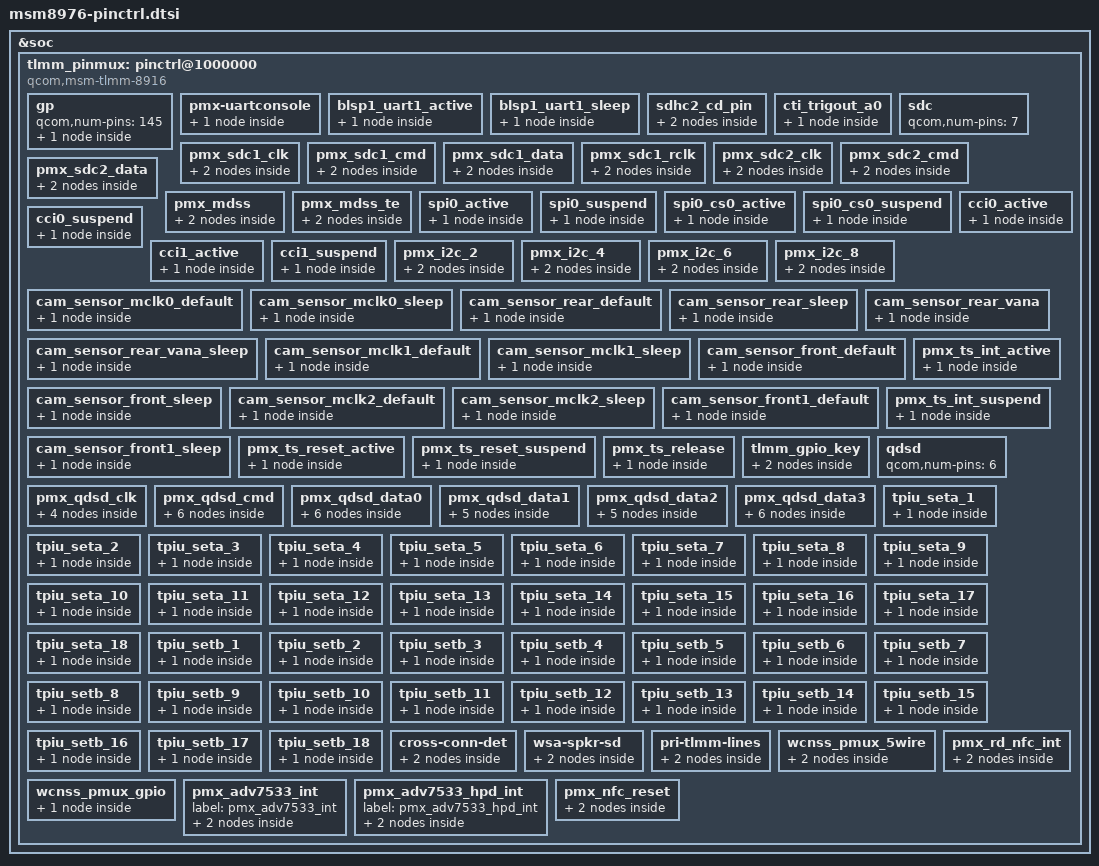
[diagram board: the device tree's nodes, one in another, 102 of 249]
/*
 * Copyright (c) 2014-2015, The Linux Foundation. All rights reserved.
 *
 * This program is free software; you can redistribute it and/or modify
 * it under the terms of the GNU General Public License version 2 and
 * only version 2 as published by the Free Software Foundation.
 *
 * This program is distributed in the hope that it will be useful,
 * but WITHOUT ANY WARRANTY; without even the implied warranty of
 * MERCHANTABILITY or FITNESS FOR A PARTICULAR PURPOSE.  See the
 * GNU General Public License for more details.
 */

&soc {
	tlmm_pinmux: pinctrl@1000000 {
		compatible = "qcom,msm-tlmm-8916";
		reg = <0x1000000 0x300000>;
		interrupts = <0 208 0>;

		/*General purpose pins*/
		gp: gp {
			qcom,num-pins = <145>;
			#qcom,pin-cells = <1>;
			msm_gpio: msm_gpio {
				compatible = "qcom,msm-tlmm-gp";
				gpio-controller;
				#gpio-cells = <2>;
				interrupt-controller;
				#interrupt-cells = <2>;
				num_irqs = <145>;
			};
		};

		pmx-uartconsole {
			qcom,pins = <&gp 4>, <&gp 5>;
			qcom,num-grp-pins = <2>;
			qcom,pin-func = <2>;
			label = "uart-console";
			uart_console_sleep: uart-console {
				drive-strength = <2>;
				bias-pull-down;
			};
		};

		blsp1_uart1_active {
			qcom,pins = <&gp 0>, <&gp 1>, <&gp 2>, <&gp 3>;
			qcom,num-grp-pins = <4>;
			qcom,pin-func = <2>;
			label = "blsp1_uart1_active";
			hsuart_active: default {
				drive-strength = <16>;
				bias-disable;
			};
		 };

		blsp1_uart1_sleep {
			qcom,pins = <&gp 0>, <&gp 1>, <&gp 2>, <&gp 3>;
			qcom,num-grp-pins = <4>;
			qcom,pin-func = <0>;
			label = "blsp1_uart1_sleep";
			hsuart_sleep: sleep {
				drive-strength = <2>;
				bias-disable;
			};
		};

		sdhc2_cd_pin {
			qcom,pins = <&gp 100>;
			qcom,num-grp-pins = <1>;
			qcom,pin-func = <0>;
			label = "cd-gpio";
			sdc2_cd_on: cd_on {
				drive-strength = <2>;
				bias-pull-up;
			};
			sdc2_cd_off: cd_off {
				drive-strength = <2>;
				bias-disable;
			};
		};

		cti_trigout_a0 {
			qcom,pins = <&gp 32>;
			qcom,num-grp-pins = <1>;
			qcom,pin-func = <8>;
			label = "cti-trigout-a0";
			trigout_a0: trigout_a0 {
				drive-strength = <2>;
				bias-disable;
			};
		};

		/* SDC pin type */
		sdc: sdc {
			/*
			 * 0-3 for sdc1
			 * 4-6 for sdc2
			 */
			qcom,num-pins = <7>;
			/*
			 * Order of pins:
			 * SDC1: CLK -> 0, CMD -> 1, DATA -> 2, RCLK -> 3
			 * SDC2: CLK -> 4, CMD -> 5, DATA -> 6
			 */
			#qcom,pin-cells = <1>;
		};

		pmx_sdc1_clk {
			qcom,pins = <&sdc 0>;
			qcom,num-grp-pins = <1>;
			label = "sdc1-clk";
			sdc1_clk_on: clk_on {
				bias-disable; /* NO pull */
				drive-strength = <16>; /* 16 MA */
			};
			sdc1_clk_off: clk_off {
				bias-disable; /* NO pull */
				drive-strength = <2>; /* 2 MA */
			};
		};

		pmx_sdc1_cmd {
			qcom,pins = <&sdc 1>;
			qcom,num-grp-pins = <1>;
			label = "sdc1-cmd";
			sdc1_cmd_on: cmd_on {
				bias-pull-up; /* pull up */
				drive-strength = <10>; /* 10 MA */
			};
			sdc1_cmd_off: cmd_off {
				bias-pull-up; /* pull up */
				drive-strength = <2>; /* 2 MA */
			};
		};

		pmx_sdc1_data {
			qcom,pins = <&sdc 2>;
			qcom,num-grp-pins = <1>;
			label = "sdc1-data";
			sdc1_data_on: data_on {
				bias-pull-up; /* pull up */
				drive-strength = <10>; /* 10 MA */
			};
			sdc1_data_off: data_off {
				bias-pull-up; /* pull up */
				drive-strength = <2>; /* 2 MA */
			};
		};

		pmx_sdc1_rclk {
			qcom,pins = <&sdc 3>;
			qcom,num-grp-pins = <1>;
			label = "sdc1-rclk";
			sdc1_rclk_on: rclk_on {
				bias-pull-down; /* pull down */
			};

			sdc1_rclk_off: rclk_off {
				bias-pull-down; /* pull down */
			};
		};

		pmx_sdc2_clk {
			qcom,pins = <&sdc 4>;
			qcom,num-grp-pins = <1>;
			label = "sdc2-clk";
			sdc2_clk_on: clk_on {
				bias-disable; /* NO pull */
				drive-strength = <16>; /* 16 MA */
			};
			sdc2_clk_off: clk_off {
				bias-disable; /* NO pull */
				drive-strength = <2>; /* 2 MA */
			};
		};

		pmx_sdc2_cmd {
			qcom,pins = <&sdc 5>;
			qcom,num-grp-pins = <1>;
			label = "sdc2-cmd";
			sdc2_cmd_on: cmd_on {
				bias-pull-up; /* pull up */
				drive-strength = <10>; /* 10 MA */
			};
			sdc2_cmd_off: cmd_off {
				bias-pull-up; /* pull up */
				drive-strength = <2>; /* 2 MA */
			};
		};

		pmx_sdc2_data {
			qcom,pins = <&sdc 6>;
			qcom,num-grp-pins = <1>;
			label = "sdc2-data";
			sdc2_data_on: data_on {
				bias-pull-up; /* pull up */
				drive-strength = <10>; /* 10 MA */
			};
			sdc2_data_off: data_off {
				bias-pull-up; /* pull up */
				drive-strength = <2>; /* 2 MA */
			};
		};

		pmx_mdss: pmx_mdss {
			label = "mdss-pins";
			qcom,pin-func = <0>;
			mdss_dsi_active: active {
				drive-strength = <8>; /* 8 mA */
				bias-disable = <0>; /* no pull */
				output-high;
			};

			mdss_dsi_suspend: suspend {
				drive-strength = <2>; /* 2 mA */
				bias-pull-down; /* pull down */
				output-low;
			};
		};

		pmx_mdss_te: pmx_mdss_te {
			label = "mdss-te-pin";
			qcom,pin-func = <1>;
			mdss_te_active: active {
				drive-strength = <2>; /* 2 mA */
				bias-pull-down; /* pull down */
				input-debounce = <0>;
			};

			mdss_te_suspend: suspend {
				drive-strength = <2>; /* 2 mA */
				bias-pull-down; /* pull down */
				input-debounce = <0>;
			};
		};

		spi0_active {
			/* MOSI, MISO, CLK */
			qcom,pins = <&gp 0>, <&gp 1>, <&gp 3>;
			qcom,num-grp-pins = <3>;
			qcom,pin-func = <1>;
			label = "spi0-active";
			/* active state */
			spi0_default: spi0_default {
				drive-strength = <12>; /* 12 MA */
				bias-disable = <0>; /* No PULL */
			};
		};

		spi0_suspend {
			/* MOSI, MISO, CLK */
			qcom,pins = <&gp 0>, <&gp 1>, <&gp 3>;
			qcom,num-grp-pins = <3>;
			qcom,pin-func = <0>;
			label = "spi0-suspend";
			/* suspended state */
			spi0_sleep: spi0_sleep {
				drive-strength = <2>; /* 2 MA */
				bias-pull-down; /* PULL Down */
			};
		};

		spi0_cs0_active {
			/* CS */
			qcom,pins = <&gp 2>;
			qcom,num-grp-pins = <1>;
			qcom,pin-func = <1>;
			label = "spi0-cs0-active";
			spi0_cs0_active: cs0_active {
				drive-strength = <2>;
				bias-disable = <0>;
			};
		};

		spi0_cs0_suspend {
			/* CS */
			qcom,pins = <&gp 2>;
			qcom,num-grp-pins = <1>;
			qcom,pin-func = <0>;
			label = "spi0-cs0-suspend";
			spi0_cs0_sleep: cs0_sleep {
				drive-strength = <2>;
				bias-disable = <0>;
			};
		};

		/* cci */
		cci0_active {
			/* CLK, DATA */
			qcom,pins = <&gp 30>, <&gp 29>;
			qcom,num-grp-pins = <2>;
			qcom,pin-func = <1>;
			label = "cci0-active";
			/* active state */
			cci0_active: cci0_active {
				drive-strength = <2>; /* 2 MA */
				bias-disable; /* No PULL */
			};
		};

		cci0_suspend {
			/* CLK, DATA */
			qcom,pins = <&gp 30>, <&gp 29>;
			qcom,num-grp-pins = <2>;
			qcom,pin-func = <0>;
			label = "cci0-suspend";
			/*suspended state */
			cci0_suspend: cci0_suspend {
				drive-strength = <2>; /* 2 MA */
				bias-disable; /* No PULL */
			};
		};

		cci1_active {
			/* CLK, DATA */
			qcom,pins = <&gp 104>, <&gp 103>;
			qcom,num-grp-pins = <2>;
			qcom,pin-func = <1>;
			label = "cci1-active";
			/* active state */
			cci1_active: cci1_active {
				drive-strength = <2>; /* 2 MA */
				bias-disable; /* No PULL */
			};
		};

		cci1_suspend {
			/* CLK, DATA */
			qcom,pins = <&gp 104>, <&gp 103>;
			qcom,num-grp-pins = <2>;
			qcom,pin-func = <0>;
			label = "cci1-suspend";
			/*suspended state */
			cci1_suspend: cci1_suspend {
				drive-strength = <2>; /* 2 MA */
				bias-disable; /* No PULL */
			};
		};

		pmx_i2c_2 {
                        /* CLK, DATA */
                        qcom,pins = <&gp 6>, <&gp 7>;
                        qcom,num-grp-pins = <2>;
                        qcom,pin-func = <3>;
                        label = "pmx_i2c_2";
			/* active state */
                        i2c_2_active: i2c_2_active {
				drive-strength = <2>; /* 2 MA */
				bias-disable = <0>; /* No PULL */
                        };
			/* suspend state */
                        i2c_2_sleep: i2c_2_sleep {
				drive-strength = <2>; /* 2 MA */
				bias-disable = <0>; /* No PULL */
                        };
                };

		pmx_i2c_4 {
			/* CLK, DATA */
			qcom,pins = <&gp 14>, <&gp 15>;
			qcom,num-grp-pins = <2>;
			qcom,pin-func = <3>;
			label = "pmx_i2c_4";
			/* active state */
			i2c_4_active: i2c_4_active {
				drive-strength = <2>; /* 2 MA */
				bias-disable = <0>; /* No PULL */
			};
                        /* suspended state */
                        i2c_4_sleep: i2c_4_sleep {
                                drive-strength = <2>; /* 2 MA */
                                bias-disable = <0>; /* No PULL */
                        };
                };

		pmx_i2c_6 {
			/* CLK, DATA */
			qcom,pins = <&gp 22>, <&gp 23>;
			qcom,num-grp-pins = <2>;
			qcom,pin-func = <3>;
			label = "pmx_i2c_6";
			/* active state */
			i2c_6_active: i2c_6_active{
				drive-strength = <2>; /* 2 MA */
				bias-disable; /* No PULL */
			};
			/* suspended state */
			i2c_6_sleep: i2c_6_sleep {
				drive-strength = <2>; /* 2 MA */
				bias-disable; /* No PULL */
			};
		};

		pmx_i2c_8 {
                        /* CLK, DATA */
                        qcom,pins = <&gp 18>, <&gp 19>;
                        qcom,num-grp-pins = <2>;
                        qcom,pin-func = <3>;
                        label = "pmx_i2c_8";
                        /* active state */
                        i2c_8_active: i2c_8_active{
                                drive-strength = <2>; /* 2 MA */
                                bias-disable; /* No PULL */
                        };
                        /* suspended state */
                        i2c_8_sleep: i2c_8_sleep {
                                drive-strength = <2>; /* 2 MA */
                                bias-disable; /* No PULL */
                        };
                };

		/*sensors */
		cam_sensor_mclk0_default {
			/* MCLK0 */
			qcom,pins = <&gp 26>;
			qcom,num-grp-pins = <1>;
			qcom,pin-func = <1>;
			label = "cam_sensor_mclk0_default";
			/* active state */
			cam_sensor_mclk0_default: cam_sensor_mclk0_default {
				drive-strength = <2>; /* 2 MA */
				bias-disable; /* No PULL */
			};
		};

		cam_sensor_mclk0_sleep {
			/* MCLK0 */
			qcom,pins = <&gp 26>;
			qcom,num-grp-pins = <1>;
			label = "cam_sensor_mclk0_sleep";
			/*suspended state */
			cam_sensor_mclk0_sleep: cam_sensor_mclk0_sleep {
				drive-strength = <2>; /* 2 MA */
				bias-pull-down; /* PULL DOWN */
			};
		};

		cam_sensor_rear_default {
			/* RESET, STANDBY */
			qcom,pins = <&gp 129>, <&gp 35>;
			qcom,num-grp-pins = <2>;
			label = "cam_sensor_rear_default";
			/* active state */
			cam_sensor_rear_default: cam_sensor_rear_default {
				drive-strength = <2>; /* 2 MA */
				bias-disable; /* No PULL */
			};
		};

		cam_sensor_rear_sleep {
			/* RESET, STANDBY */
			qcom,pins = <&gp 129>, <&gp 35>;
			qcom,num-grp-pins = <2>;
			label = "cam_sensor_rear_sleep";
			/*suspended state */
			cam_sensor_rear_sleep: cam_sensor_rear_sleep {
				drive-strength = <2>; /* 2 MA */
				bias-disable; /* No PULL */
			};
		};

		cam_sensor_rear_vana {
			/* VANA */
			qcom,pins = <&gp 63>;
			qcom,num-grp-pins = <1>;
			label = "cam_sensor_rear_vana";
			/* active state */
			cam_sensor_rear_vana: cam_sensor_rear_vana {
				drive-strength = <2>; /* 2 MA */
				bias-disable; /* No PULL */
			};
		};

		cam_sensor_rear_vana_sleep {
			/* VANA */
			qcom,pins = <&gp 63>;
			qcom,num-grp-pins = <1>;
			label = "cam_sensor_rear_vana_sleep";
			/*suspended state */
			cam_sensor_rear_vana_sleep: cam_sensor_rear_vana_sleep {
				drive-strength = <2>; /* 2 MA */
				bias-disable; /* No PULL */
			};
		};

		cam_sensor_mclk1_default {
			/* MCLK1 */
			qcom,pins = <&gp 27>;
			qcom,num-grp-pins = <1>;
			qcom,pin-func = <1>;
			label = "cam_sensor_mclk1_default";
			/* active state */
			cam_sensor_mclk1_default: cam_sensor_mclk1_default {
				drive-strength = <2>; /* 2 MA */
				bias-disable; /* No PULL */
			};
		};

		cam_sensor_mclk1_sleep {
			/* MCLK1 */
			qcom,pins = <&gp 27>;
			qcom,num-grp-pins = <1>;
			label = "cam_sensor_mclk1_sleep";
			/*suspended state */
			cam_sensor_mclk1_sleep: cam_sensor_mclk1_sleep {
				drive-strength = <2>; /* 2 MA */
				bias-pull-down; /* PULL DOWN */
			};
		};

		cam_sensor_front_default {
			/* RESET, STANDBY */
			qcom,pins = <&gp 130>, <&gp 36>;
			qcom,num-grp-pins = <2>;
			label = "cam_sensor_front_default";
			/* active state */
			cam_sensor_front_default: cam_sensor_front_default {
				drive-strength = <2>; /* 2 MA */
				bias-disable; /* No PULL */
			};
		};

		cam_sensor_front_sleep {
			/* RESET, STANDBY */
			qcom,pins = <&gp 130>, <&gp 36>;
			qcom,num-grp-pins = <2>;
			label = "cam_sensor_front_sleep";
			/*suspended state */
			cam_sensor_front_sleep: cam_sensor_front_sleep {
				drive-strength = <2>; /* 2 MA */
				bias-disable; /* No PULL */
			};
		};

		cam_sensor_mclk2_default {
			/* MCLK2 */
			qcom,pins = <&gp 28>;
			qcom,num-grp-pins = <1>;
			qcom,pin-func = <1>;
			label = "cam_sensor_mclk2_default";
			/* active state */
			cam_sensor_mclk2_default: cam_sensor_mclk2_default {
				drive-strength = <2>; /* 2 MA */
				bias-disable; /* No PULL */
			};
		};

		cam_sensor_mclk2_sleep {
			/* MCLK2 */
			qcom,pins = <&gp 28>;
			qcom,num-grp-pins = <1>;
			label = "cam_sensor_mclk2_sleep";
			/*suspended state */
			cam_sensor_mclk2_sleep: cam_sensor_mclk2_sleep {
				drive-strength = <2>; /* 2 MA */
				bias-pull-down; /* PULL DOWN */
			};
		};

		cam_sensor_front1_default {
			/* RESET, STANDBY */
			qcom,pins = <&gp 131>, <&gp 38>;
			qcom,num-grp-pins = <2>;
			label = "cam_sensor_front1_default";
			/* active state */
			cam_sensor_front1_default: cam_sensor_front1_default {
				drive-strength = <2>; /* 2 MA */
				bias-disable; /* No PULL */
			};
		};

		cam_sensor_front1_sleep {
			/* RESET, STANDBY */
			qcom,pins = <&gp 131>, <&gp 38>;
			qcom,num-grp-pins = <2>;
			label = "cam_sensor_front1_sleep";
			/*suspended state */
			cam_sensor_front1_sleep: cam_sensor_front1_sleep {
				drive-strength = <2>; /* 2 MA */
				bias-disable; /* No PULL */
			};
		};

		/* add pingrp for touchscreen */
		pmx_ts_int_active {
			qcom,pins = <&gp 65>;
			qcom,pin-func = <0>;
			qcom,num-grp-pins = <1>;
			label = "pmx_ts_int_active";

			ts_int_active: ts_int_active {
				drive-strength = <8>;
				bias-pull-up;
			};
		};

		pmx_ts_int_suspend {
			qcom,pins = <&gp 65>;
			qcom,pin-func = <0>;
			qcom,num-grp-pins = <1>;
			label = "pmx_ts_int_suspend";

			ts_int_suspend: ts_int_suspend {
				drive-strength = <2>;
				bias-pull-down;
			};
		};

		pmx_ts_reset_active {
			qcom,pins = <&gp 64>;
			qcom,pin-func = <0>;
			qcom,num-grp-pins = <1>;
			label = "pmx_ts_reset_active";

			ts_reset_active: ts_reset_active {
				drive-strength = <8>;
				bias-pull-up;
			};
		};

		pmx_ts_reset_suspend {
			qcom,pins = <&gp 64>;
			qcom,pin-func = <0>;
			qcom,num-grp-pins = <1>;
			label = "pmx_ts_reset_suspend";

			ts_reset_suspend: ts_reset_suspend {
				drive-strength = <2>;
				bias-pull-down;
			};
		};

		pmx_ts_release {
			qcom,pins = <&gp 65>, <&gp 64>;
			qcom,num-grp-pins = <2>;
			label = "pmx_ts_release";

			ts_release: ts_release {
				drive-strength = <2>;
				bias-pull-down;
			};
		};

		tlmm_gpio_key {
			qcom,pins = <&gp 113>, <&gp 114>, <&gp 115>;
			qcom,pin-func = <0>;
			qcom,num-grp-pins = <3>;
			label = "tlmm_gpio_key";

			gpio_key_active: gpio_key_active {
				drive-strength = <2>;
				bias-pull-up;
			};

			gpio_key_suspend: gpio_key_suspend {
				drive-strength = <2>;
				bias-pull-up;
			};
		};

		/* QDSD pin type */
		qdsd: qdsd {
			/* 0-> clk, 1 -> cmd, 2->data0, 3->data1, 4->data2, 5->data3 */
			qcom,num-pins = <6>;

			#qcom,pin-cells = <1>;
		};

		pmx_qdsd_clk {
			qcom,pins = <&qdsd 0>;
			qcom,num-grp-pins = <1>;
			label = "qdsd-clk";
			qdsd_clk_sdcard: clk_sdcard {
				bias-disable; /* NO pull */
				drive-strength = <7>; /* 7 MA */
			};

			qdsd_clk_trace: clk_trace {
				bias-pull-down; /* pull down */
				drive-strength = <0>; /* 0 MA */
			};

			qdsd_clk_swdtrc: clk_swdtrc {
				bias-pull-down; /* pull down */
				drive-strength = <0>; /* 0 MA */
			};

			qdsd_clk_spmi: clk_spmi {
				bias-pull-down; /* pull down */
				drive-strength = <0>; /* 0 MA */
			};
		};

		pmx_qdsd_cmd {
			qcom,pins = <&qdsd 1>;
			qcom,num-grp-pins = <1>;
			label = "qdsd-cmd";
			qdsd_cmd_sdcard: cmd_sdcard {
				bias-pull-down; /* pull down */
				drive-strength = <3>; /* 3 MA */
			};

			qdsd_cmd_trace: cmd_trace {
				bias-pull-down; /* pull down */
				drive-strength = <0>; /* 0 MA */
			};

			qdsd_cmd_swduart: cmd_uart {
				bias-pull-up; /* pull up */
				drive-strength = <0>; /* 0 MA */
			};

			qdsd_cmd_swdtrc: cmd_swdtrc {
				bias-pull-up; /* pull up */
				drive-strength = <0>; /* 0 MA */
			};

			qdsd_cmd_jtag: cmd_jtag {
				bias-disable; /* NO pull */
				drive-strength = <3>; /* 3 MA */
			};

			qdsd_cmd_spmi: cmd_spmi {
				bias-pull-down; /* pull down */
				drive-strength = <4>; /* 4 MA */
			};
		};

		pmx_qdsd_data0 {
			qcom,pins = <&qdsd 2>;
			qcom,num-grp-pins = <1>;
			label = "qdsd-data0";
			qdsd_data0_sdcard: data0_sdcard {
				bias-pull-down; /* pull down */
				drive-strength = <3>; /* 3 MA */
			};

			qdsd_data0_trace: data0_trace {
				bias-pull-down; /* pull down */
				drive-strength = <3>; /* 3 MA */
			};

			qdsd_data0_swduart: data0_uart {
				bias-pull-down; /* pull down */
				drive-strength = <0>; /* 0 MA */
			};

			qdsd_data0_swdtrc: data0_swdtrc {
				bias-pull-down; /* pull down */
				drive-strength = <0>; /* 0 MA */
			};

			qdsd_data0_jtag: data0_jtag {
				bias-pull-up; /* pull up */
				drive-strength = <0>; /* 0 MA */
			};

			qdsd_data0_spmi: data0_spmi {
				bias-pull-down; /* pull down */
				drive-strength = <0>; /* 0 MA */
			};
		};

		pmx_qdsd_data1 {
			qcom,pins = <&qdsd 3>;
			qcom,num-grp-pins = <1>;
			label = "qdsd-data1";
			qdsd_data1_sdcard: data1_sdcard {
				bias-pull-down; /* pull down */
				drive-strength = <3>; /* 3 MA */
			};

			qdsd_data1_trace: data1_trace {
				bias-pull-down; /* pull down */
				drive-strength = <3>; /* 3 MA */
			};

			qdsd_data1_swduart: data1_uart {
				bias-pull-down; /* pull down */
				drive-strength = <0>; /* 0 MA */
			};

			qdsd_data1_swdtrc: data1_swdtrc {
				bias-pull-down; /* pull down */
				drive-strength = <0>; /* 0 MA */
			};

			qdsd_data1_jtag: data1_jtag {
				bias-pull-down; /* pull down */
				drive-strength = <0>; /* 0 MA */
			};
		};

		pmx_qdsd_data2 {
			qcom,pins = <&qdsd 4>;
			qcom,num-grp-pins = <1>;
			label = "qdsd-data2";
			qdsd_data2_sdcard: data2_sdcard {
				bias-pull-down; /* pull down */
				drive-strength = <3>; /* 3 MA */
			};

			qdsd_data2_trace: data2_trace {
				bias-pull-down; /* pull down */
				drive-strength = <3>; /* 3 MA */
			};

			qdsd_data2_swduart: data2_uart {
				bias-pull-down; /* pull down */
				drive-strength = <0>; /* 0 MA */
			};

			qdsd_data2_swdtrc: data2_swdtrc {
				bias-pull-down; /* pull down */
				drive-strength = <0>; /* 0 MA */
			};

			qdsd_data2_jtag: data2_jtag {
				bias-pull-up; /* pull up */
				drive-strength = <3>; /* 3 MA */
			};
		};

		pmx_qdsd_data3 {
			qcom,pins = <&qdsd 5>;
			qcom,num-grp-pins = <1>;
			label = "qdsd-data3";
			qdsd_data3_sdcard: data3_sdcard {
				bias-pull-down; /* pull down */
				drive-strength = <3>; /* 3 MA */
			};

			qdsd_data3_trace: data3_trace {
				bias-pull-down; /* pull down */
				drive-strength = <3>; /* 3 MA */
			};

			qdsd_data3_swduart: data3_uart {
				bias-pull-up; /* pull up */
				drive-strength = <0>; /* 0 MA */
			};

			qdsd_data3_swdtrc: data3_swdtrc {
				bias-pull-up; /* pull up */
				drive-strength = <0>; /* 0 MA */
			};

			qdsd_data3_jtag: data3_jtag {
				bias-pull-up; /* pull up */
				drive-strength = <0>; /* 0 MA */
			};

			qdsd_data3_spmi: data3_spmi {
				bias-pull-down; /* pull down */
				drive-strength = <3>; /* 3 MA */
			};
		};

		/* CoreSight */
		tpiu_seta_1 {
			qcom,pins = <&gp 8>;
			qcom,num-grp-pins = <1>;
			qcom,pin-func = <6>;
			label = "tpiu-seta-1";
			seta_1: seta {
				drive-strength = <16>;
				bias-disable;
			};
		};

		tpiu_seta_2 {
			qcom,pins = <&gp 9>;
			qcom,num-grp-pins = <1>;
			qcom,pin-func = <5>;
			label = "tpiu-seta-2";
			seta_2: seta {
				drive-strength = <16>;
				bias-disable;
			};
		};

		tpiu_seta_3 {
			qcom,pins = <&gp 10>;
			qcom,num-grp-pins = <1>;
			qcom,pin-func = <6>;
			label = "tpiu-seta-3";
			seta_3: seta {
				drive-strength = <16>;
				bias-disable;
			};
		};

		tpiu_seta_4 {
			qcom,pins = <&gp 39>;
			qcom,num-grp-pins = <1>;
			qcom,pin-func = <4>;
			label = "tpiu-seta-4";
			seta_4: seta {
				drive-strength = <16>;
				bias-disable;
			};
		};

		tpiu_seta_5 {
			qcom,pins = <&gp 40>;
			qcom,num-grp-pins = <1>;
			qcom,pin-func = <4>;
			label = "tpiu-seta-5";
			seta_5: seta {
				drive-strength = <16>;
				bias-disable;
			};
		};

		tpiu_seta_6 {
			qcom,pins = <&gp 41>;
			qcom,num-grp-pins = <1>;
			qcom,pin-func = <4>;
			label = "tpiu-seta-6";
			seta_6: seta {
				drive-strength = <16>;
				bias-disable;
			};
		};

		tpiu_seta_7 {
			qcom,pins = <&gp 42>;
			qcom,num-grp-pins = <1>;
			qcom,pin-func = <4>;
			label = "tpiu-seta-7";
			seta_7: seta {
				drive-strength = <16>;
				bias-disable;
			};
		};

		tpiu_seta_8 {
			qcom,pins = <&gp 43>;
			qcom,num-grp-pins = <1>;
			qcom,pin-func = <5>;
			label = "tpiu-seta-8";
			seta_8: seta {
				drive-strength = <16>;
				bias-disable;
			};
		};

		tpiu_seta_9 {
			qcom,pins = <&gp 45>;
			qcom,num-grp-pins = <1>;
			qcom,pin-func = <3>;
			label = "tpiu-seta-9";
			seta_9: seta {
				drive-strength = <16>;
				bias-disable;
			};
		};

		tpiu_seta_10 {
			qcom,pins = <&gp 46>;
			qcom,num-grp-pins = <1>;
			qcom,pin-func = <4>;
			label = "tpiu-seta-10";
			seta_10: seta {
				drive-strength = <16>;
				bias-disable;
			};
		};

		tpiu_seta_11 {
			qcom,pins = <&gp 47>;
			qcom,num-grp-pins = <1>;
			qcom,pin-func = <3>;
			label = "tpiu-seta-11";
			seta_11: seta {
				drive-strength = <16>;
				bias-disable;
			};
		};

		tpiu_seta_12 {
			qcom,pins = <&gp 48>;
			qcom,num-grp-pins = <1>;
			qcom,pin-func = <3>;
			label = "tpiu-seta-12";
			seta_12: seta {
				drive-strength = <16>;
				bias-disable;
			};
		};

		tpiu_seta_13 {
			qcom,pins = <&gp 62>;
			qcom,num-grp-pins = <1>;
			qcom,pin-func = <3>;
			label = "tpiu-seta-13";
			seta_13: seta {
				drive-strength = <16>;
				bias-disable;
			};
		};

		tpiu_seta_14 {
			qcom,pins = <&gp 69>;
			qcom,num-grp-pins = <1>;
			qcom,pin-func = <1>;
			label = "tpiu-seta-14";
			seta_14: seta {
				drive-strength = <16>;
				bias-disable;
			};
		};

		tpiu_seta_15 {
			qcom,pins = <&gp 120>;
			qcom,num-grp-pins = <1>;
			qcom,pin-func = <8>;
			label = "tpiu-seta-15";
			seta_15: seta {
				drive-strength = <16>;
				bias-disable;
			};
		};

		tpiu_seta_16 {
			qcom,pins = <&gp 121>;
			qcom,num-grp-pins = <1>;
			qcom,pin-func = <8>;
			label = "tpiu-seta-16";
			seta_16: seta {
				drive-strength = <16>;
				bias-disable;
			};
		};

		tpiu_seta_17 {
			qcom,pins = <&gp 130>;
			qcom,num-grp-pins = <1>;
			qcom,pin-func = <1>;
			label = "tpiu-seta-17";
			seta_17: seta {
				drive-strength = <16>;
				bias-disable;
			};
		};

		tpiu_seta_18 {
			qcom,pins = <&gp 131>;
			qcom,num-grp-pins = <1>;
			qcom,pin-func = <1>;
			label = "tpiu-seta-18";
			seta_18: seta {
				drive-strength = <16>;
				bias-disable;
			};
		};

		tpiu_setb_1 {
			qcom,pins = <&gp 4>;
			qcom,num-grp-pins = <1>;
			qcom,pin-func = <6>;
			label = "tpiu-setb-1";
			setb_1: setb {
				drive-strength = <16>;
				bias-disable;
			};
		};

		tpiu_setb_2 {
			qcom,pins = <&gp 5>;
			qcom,num-grp-pins = <1>;
			qcom,pin-func = <6>;
			label = "tpiu-setb-2";
			setb_2: setb {
				drive-strength = <16>;
				bias-disable;
			};
		};

		tpiu_setb_3 {
			qcom,pins = <&gp 26>;
			qcom,num-grp-pins = <1>;
			qcom,pin-func = <6>;
			label = "tpiu-setb-3";
			setb_3: setb {
				drive-strength = <16>;
				bias-disable;
			};
		};

		tpiu_setb_4 {
			qcom,pins = <&gp 27>;
			qcom,num-grp-pins = <1>;
			qcom,pin-func = <7>;
			label = "tpiu-setb-4";
			setb_4: setb {
				drive-strength = <16>;
				bias-disable;
			};
		};

		tpiu_setb_5 {
			qcom,pins = <&gp 28>;
			qcom,num-grp-pins = <1>;
			qcom,pin-func = <6>;
			label = "tpiu-setb-5";
			setb_5: setb {
				drive-strength = <16>;
				bias-disable;
			};
		};

		tpiu_setb_6 {
			qcom,pins = <&gp 29>;
			qcom,num-grp-pins = <1>;
			qcom,pin-func = <6>;
			label = "tpiu-setb-6";
			setb_6: setb {
				drive-strength = <16>;
				bias-disable;
			};
		};

		tpiu_setb_7 {
			qcom,pins = <&gp 30>;
			qcom,num-grp-pins = <1>;
			qcom,pin-func = <7>;
			label = "tpiu-setb-7";
			setb_7: setb {
				drive-strength = <16>;
				bias-disable;
			};
		};

		tpiu_setb_8 {
			qcom,pins = <&gp 31>;
			qcom,num-grp-pins = <1>;
			qcom,pin-func = <8>;
			label = "tpiu-setb-8";
			setb_8: setb {
				drive-strength = <16>;
				bias-disable;
			};
		};

		tpiu_setb_9 {
			qcom,pins = <&gp 33>;
			qcom,num-grp-pins = <1>;
			qcom,pin-func = <7>;
			label = "tpiu-setb-9";
			setb_9: setb {
				drive-strength = <16>;
				bias-disable;
			};
		};

		tpiu_setb_10 {
			qcom,pins = <&gp 34>;
			qcom,num-grp-pins = <1>;
			qcom,pin-func = <9>;
			label = "tpiu-setb-10";
			setb_10: setb {
				drive-strength = <16>;
				bias-disable;
			};
		};

		tpiu_setb_11 {
			qcom,pins = <&gp 35>;
			qcom,num-grp-pins = <1>;
			qcom,pin-func = <9>;
			label = "tpiu-setb-11";
			setb_11: setb {
				drive-strength = <16>;
				bias-disable;
			};
		};

		tpiu_setb_12 {
			qcom,pins = <&gp 36>;
			qcom,num-grp-pins = <1>;
			qcom,pin-func = <7>;
			label = "tpiu-setb-12";
			setb_12: setb {
				drive-strength = <16>;
				bias-disable;
			};
		};

		tpiu_setb_13 {
			qcom,pins = <&gp 37>;
			qcom,num-grp-pins = <1>;
			qcom,pin-func = <4>;
			label = "tpiu-setb-13";
			setb_13: setb {
				drive-strength = <16>;
				bias-disable;
			};
		};

		tpiu_setb_14 {
			qcom,pins = <&gp 38>;
			qcom,num-grp-pins = <1>;
			qcom,pin-func = <8>;
			label = "tpiu-setb-14";
			setb_14: setb {
				drive-strength = <16>;
				bias-disable;
			};
		};

		tpiu_setb_15 {
			qcom,pins = <&gp 116>;
			qcom,num-grp-pins = <1>;
			qcom,pin-func = <6>;
			label = "tpiu-setb-15";
			setb_15: setb {
				drive-strength = <16>;
				bias-disable;
			};
		};

		tpiu_setb_16 {
			qcom,pins = <&gp 126>;
			qcom,num-grp-pins = <1>;
			qcom,pin-func = <9>;
			label = "tpiu-setb-16";
			setb_16: setb {
				drive-strength = <16>;
				bias-disable;
			};
		};

		tpiu_setb_17 {
			qcom,pins = <&gp 128>;
			qcom,num-grp-pins = <1>;
			qcom,pin-func = <7>;
			label = "tpiu-setb-17";
			setb_17: setb {
				drive-strength = <16>;
				bias-disable;
			};
		};

		tpiu_setb_18 {
			qcom,pins = <&gp 129>;
			qcom,num-grp-pins = <1>;
			qcom,pin-func = <1>;
			label = "tpiu-setb-18";
			setb_18: setb {
				drive-strength = <16>;
				bias-disable;
			};
		};

		cross-conn-det {
			qcom,pins = <&gp 144>;
			qcom,num-grp-pins = <1>;
			qcom,pin-func = <0>;
			label = "cross-conn-det-sw";
			cross_conn_det_act: lines_on {
				drive-strength = <8>;
				output-low;
				bias-pull-down;
			};

			cross_conn_det_sus: lines_off {
				drive-strength = <2>;
				bias-pull-down;
			};
		};

		wsa-spkr-sd {
			qcom,pins = <&gp 132>;
			qcom,num-grp-pins = <1>;
			qcom,pin-func = <0>;
			label = "wsa-spkr-sd";
			wsa_spkr_sd_act: lines_on {
					 drive-strength = <8>;
					 output-high;
					 bias-pull-down;
			};

			wsa_spkr_sd_sus: lines_off {
					 drive-strength = <2>;
					 bias-disable;
			};
		};

		pri-tlmm-lines {
			qcom,pins = <&gp 123>, <&gp 124>, <&gp 125>;
			qcom,num-grp-pins = <3>;
			qcom,pin-func = <1>;
			label = "pri-tlmm-lines";
			pri_tlmm_lines_act: pri_tlmm_lines_act {
				drive-strength = <8>;
			};
			pri_tlmm_lines_sus:  pri_tlmm_lines_sus {
				drive-strength = <2>;
				bias-pull-down;
			};
		};

		wcnss_pmux_5wire: wcnss_pmux_5wire {
			/* Uses general purpose pins */
			qcom,pins = <&gp 40>, <&gp 41>,
				    <&gp 42>, <&gp 43>,
				    <&gp 44>;
			qcom,num-grp-pins = <5>;
			qcom,pin-func = <1>;
			label = "wcnss_5wire_pins";
			/* Active configuration of bus pins */
			wcnss_default: wcnss_default {
				drive-strength = <6>; /* 6 MA */
				bias-pull-up; /* PULL UP */
			};
			wcnss_sleep: wcnss_sleep {
				drive-strength = <2>; /* 2 MA */
				bias-pull-down; /* PULL Down */
			};
		};

		wcnss_pmux_gpio: wcnss_pmux_gpio {
			/* Uses general purpose pins */
			qcom,pins = <&gp 40>, <&gp 41>,
				    <&gp 42>, <&gp 43>,
				    <&gp 44>;
			qcom,num-grp-pins = <5>;
			qcom,pin-func = <0>;
			label = "wcnss_5gpio_pins";
			/* Active configuration of bus pins */
			wcnss_gpio_default: wcnss_gpio_default {
				drive-strength = <6>; /* 6 MA */
				bias-pull-up; /* PULL UP */
			};
		};

		pmx_adv7533_int: pmx_adv7533_int {
			label = "pmx_adv7533_int";
			adv7533_int_active: adv7533_int_active {
				drive-strength = <16>;
				bias-disable;
			};

			adv7533_int_suspend: adv7533_int_suspend {
				drive-strength = <16>;
				bias-disable;
			};
		};

		pmx_adv7533_hpd_int: pmx_adv7533_hpd_int {
			label = "pmx_adv7533_hpd_int";
			adv7533_hpd_int_active: adv7533_hpd_int_active {
				drive-strength = <16>;
				bias-disable;
			};

			adv7533_hpd_int_suspend: adv7533_hpd_int_suspend {
				drive-strength = <16>;
				bias-disable;
			};
		};

		pmx_rd_nfc_int {
			qcom,pins = <&gp 21>;
			qcom,pin-func = <0>;
			qcom,num-grp-pins = <1>;
			label = "pmx_nfc_int";

			nfc_int_active: active {
				drive-strength = <6>;
				bias-pull-up;
			};

			nfc_int_suspend: suspend {
				drive-strength = <6>;
				bias-pull-up;
			};
		};

		pmx_nfc_reset {
			qcom,pins = <&gp 20>;
			qcom,pin-func = <0>;
			qcom,num-grp-pins = <1>;
			label = "pmx_nfc_disable";

			nfc_disable_active: active {
				drive-strength = <6>;
				bias-pull-up;
			};

			nfc_disable_suspend: suspend {
				drive-strength = <6>;
				bias-disable;
			};
		};
	};
};
